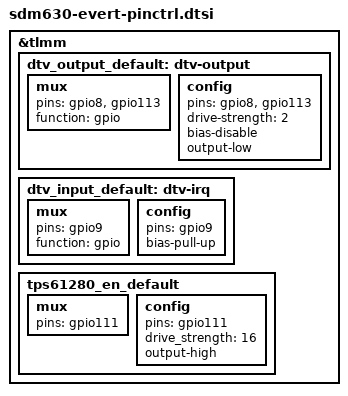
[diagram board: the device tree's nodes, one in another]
/* Copyright (c) 2017, Motorola Mobility Inc. All rights reserved.
 *
 * This program is free software; you can redistribute it and/or modify
 * it under the terms of the GNU General Public License version 2 and
 * only version 2 as published by the Free Software Foundation.
 *
 * This program is distributed in the hope that it will be useful,
 * but WITHOUT ANY WARRANTY; without even the implied warranty of
 * MERCHANTABILITY or FITNESS FOR A PARTICULAR PURPOSE.  See the
 * GNU General Public License for more details.
 */

&tlmm {
	dtv_output_default: dtv-output {
		mux {
			/* enable, reset */
			pins = "gpio8", "gpio113";
			function = "gpio";
		};
		config {
			pins = "gpio8", "gpio113";
			drive-strength = <2>; /* 2 MA */
			bias-disable ; /* No PULL */
			output-low;
		};
	};
	/* DTV interrupt pin */
	dtv_input_default: dtv-irq {
		mux {
			pins = "gpio9";
			function = "gpio";
		};
		config {
			pins = "gpio9";
			bias-pull-up; /* pull up */
		};
	};

	tps61280_en_default: tps61280_en_default {
		mux {
			pins = "gpio111";
		};
		config {
			pins = "gpio111";
			drive_strength = <16>;
			output-high;
		};
	};
};
